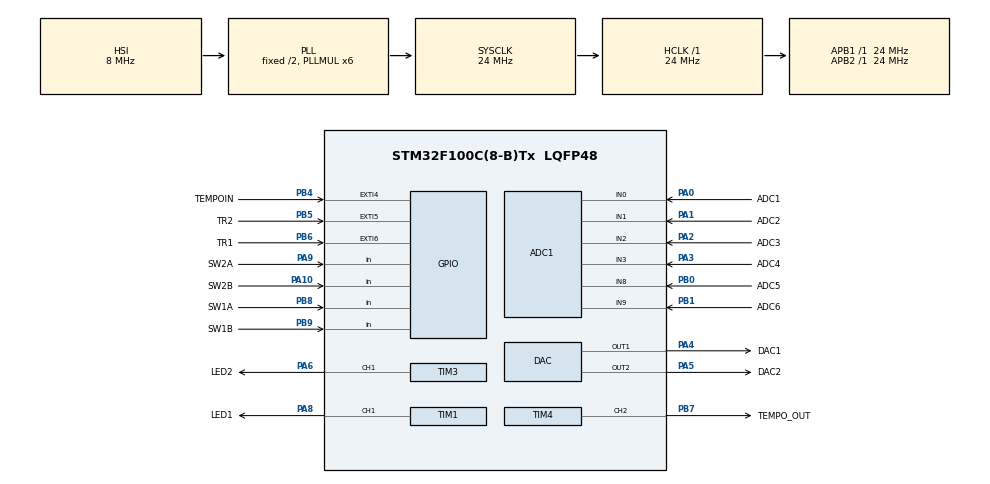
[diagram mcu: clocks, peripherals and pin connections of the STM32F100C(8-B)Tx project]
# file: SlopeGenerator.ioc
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ADC1.Channel-0\#ChannelRegularConversion=ADC_CHANNEL_0
ADC1.Channel-1\#ChannelRegularConversion=ADC_CHANNEL_1
ADC1.Channel-2\#ChannelRegularConversion=ADC_CHANNEL_2
ADC1.Channel-3\#ChannelRegularConversion=ADC_CHANNEL_3
ADC1.Channel-4\#ChannelRegularConversion=ADC_CHANNEL_8
ADC1.Channel-5\#ChannelRegularConversion=ADC_CHANNEL_9
ADC1.ContinuousConvMode=ENABLE
ADC1.DataAlign=ADC_DATAALIGN_RIGHT
ADC1.DiscontinuousConvMode=DISABLE
ADC1.EnableAnalogWatchDog=false
ADC1.EnableRegularConversion=ENABLE
ADC1.ExternalTrigConv=ADC_SOFTWARE_START
ADC1.InjNumberOfConversion=0
ADC1.NbrOfConversion=6
ADC1.NbrOfConversionFlag=1
ADC1.Rank-0\#ChannelRegularConversion=1
ADC1.Rank-1\#ChannelRegularConversion=2
ADC1.Rank-2\#ChannelRegularConversion=3
ADC1.Rank-3\#ChannelRegularConversion=4
ADC1.Rank-4\#ChannelRegularConversion=5
ADC1.Rank-5\#ChannelRegularConversion=6
ADC1.SamplingTime-0\#ChannelRegularConversion=ADC_SAMPLETIME_71CYCLES_5
ADC1.SamplingTime-1\#ChannelRegularConversion=ADC_SAMPLETIME_71CYCLES_5
ADC1.SamplingTime-2\#ChannelRegularConversion=ADC_SAMPLETIME_71CYCLES_5
ADC1.SamplingTime-3\#ChannelRegularConversion=ADC_SAMPLETIME_71CYCLES_5
ADC1.SamplingTime-4\#ChannelRegularConversion=ADC_SAMPLETIME_71CYCLES_5
ADC1.SamplingTime-5\#ChannelRegularConversion=ADC_SAMPLETIME_71CYCLES_5
ADC1.ScanConvMode=ADC_SCAN_ENABLE
ADC1.master=1
DAC.DAC_OutputBuffer=DAC_OUTPUTBUFFER_DISABLE
DAC.DAC_OutputBuffer2=DAC_OUTPUTBUFFER_DISABLE
DAC.DAC_Trigger=DAC_TRIGGER_T6_TRGO
DAC.DAC_Trigger2=DAC_TRIGGER_T6_TRGO
Dma.ADC1.2.Direction=DMA_PERIPH_TO_MEMORY
Dma.ADC1.2.Instance=DMA1_Channel1
Dma.ADC1.2.MemDataAlignment=DMA_MDATAALIGN_HALFWORD
Dma.ADC1.2.MemInc=DMA_MINC_ENABLE
Dma.ADC1.2.Mode=DMA_CIRCULAR
Dma.ADC1.2.PeriphDataAlignment=DMA_PDATAALIGN_HALFWORD
Dma.ADC1.2.PeriphInc=DMA_PINC_DISABLE
Dma.ADC1.2.Priority=DMA_PRIORITY_LOW
Dma.DAC_CH1.0.Direction=DMA_MEMORY_TO_PERIPH
Dma.DAC_CH1.0.Instance=DMA1_Channel3
Dma.DAC_CH1.0.MemDataAlignment=DMA_MDATAALIGN_HALFWORD
Dma.DAC_CH1.0.MemInc=DMA_MINC_ENABLE
Dma.DAC_CH1.0.Mode=DMA_CIRCULAR
Dma.DAC_CH1.0.PeriphDataAlignment=DMA_PDATAALIGN_HALFWORD
Dma.DAC_CH1.0.PeriphInc=DMA_PINC_DISABLE
Dma.DAC_CH1.0.Priority=DMA_PRIORITY_LOW
Dma.DAC_CH2.1.Direction=DMA_MEMORY_TO_PERIPH
Dma.DAC_CH2.1.Instance=DMA1_Channel4
Dma.DAC_CH2.1.MemDataAlignment=DMA_MDATAALIGN_HALFWORD
Dma.DAC_CH2.1.MemInc=DMA_MINC_ENABLE
Dma.DAC_CH2.1.Mode=DMA_CIRCULAR
Dma.DAC_CH2.1.PeriphDataAlignment=DMA_PDATAALIGN_HALFWORD
Dma.DAC_CH2.1.PeriphInc=DMA_PINC_DISABLE
Dma.DAC_CH2.1.Priority=DMA_PRIORITY_LOW
Dma.Request0=DAC_CH1
Dma.Request1=DAC_CH2
Dma.Request2=ADC1
Mcu.Family=STM32F1
Mcu.Name=STM32F100C(8-B)Tx
Mcu.Package=LQFP48
NVIC.DMA1_Channel1_IRQn=true\:2\:0\:true\:false\:true
NVIC.DMA1_Channel3_IRQn=true\:2\:0\:true\:false\:true
NVIC.DMA1_Channel4_IRQn=true\:2\:0\:true\:false\:true
NVIC.EXTI4_IRQn=true\:15\:0\:true\:false\:true
NVIC.EXTI9_5_IRQn=true\:15\:0\:true\:false\:true
NVIC.PriorityGroup=NVIC_PRIORITYGROUP_4
NVIC.TIM2_IRQn=true\:5\:0\:true\:false\:true
PA0-WKUP.GPIO_Label=ADC1
PA0-WKUP.Signal=ADCx_IN0
PA1.GPIO_Label=ADC2
PA1.Signal=ADCx_IN1
PA10.GPIO_Label=SW2B
PA10.GPIO_PuPd=GPIO_PULLUP
PA10.Signal=GPIO_Input
PA13.Mode=Serial_Wire
PA13.Signal=SYS_JTMS-SWDIO
PA14.Mode=Serial_Wire
PA14.Signal=SYS_JTCK-SWCLK
PA2.GPIO_Label=ADC3
PA2.Signal=ADCx_IN2
PA3.GPIO_Label=ADC4
PA3.Signal=ADCx_IN3
PA4.GPIO_Label=DAC1
PA4.Signal=COMP_DAC1_group
PA5.GPIO_Label=DAC2
PA5.Signal=COMP_DAC2_group
PA6.GPIO_Label=LED2
PA6.Signal=S_TIM3_CH1
PA8.GPIO_Label=LED1
PA8.Signal=S_TIM1_CH1
PA9.GPIO_Label=SW2A
PA9.GPIO_PuPd=GPIO_PULLUP
PA9.Signal=GPIO_Input
PB0.GPIO_Label=ADC5
PB0.Signal=ADCx_IN8
PB1.GPIO_Label=ADC6
PB1.Signal=ADCx_IN9
PB4.GPIO_Label=TEMPOIN
PB4.GPIO_ModeDefaultEXTI=GPIO_MODE_IT_FALLING
PB4.GPIO_PuPd=GPIO_PULLUP
PB4.Signal=GPXTI4
PB5.GPIO_Label=TR2
PB5.GPIO_ModeDefaultEXTI=GPIO_MODE_IT_FALLING
PB5.GPIO_PuPd=GPIO_PULLUP
PB5.Signal=GPXTI5
PB6.GPIO_Label=TR1
PB6.GPIO_ModeDefaultEXTI=GPIO_MODE_IT_FALLING
PB6.GPIO_PuPd=GPIO_PULLUP
PB6.Signal=GPXTI6
PB7.GPIO_Label=TEMPO_OUT
PB7.Signal=S_TIM4_CH2
PB8.GPIO_Label=SW1A
PB8.GPIO_PuPd=GPIO_PULLUP
PB8.Signal=GPIO_Input
PB9.GPIO_Label=SW1B
PB9.GPIO_PuPd=GPIO_PULLUP
PB9.Signal=GPIO_Input
PD0-OSC_IN.Mode=HSE-External-Oscillator
PD0-OSC_IN.Signal=RCC_OSC_IN
PD1-OSC_OUT.Mode=HSE-External-Oscillator
PD1-OSC_OUT.Signal=RCC_OSC_OUT
ProjectManager.HeapSize=0x200
ProjectManager.StackSize=0x400
ProjectManager.TargetToolchain=TrueSTUDIO
RCC.ADCPresc=RCC_ADCPCLK2_DIV8
RCC.AHBFreq_Value=24000000
RCC.APB1Freq_Value=24000000
RCC.APB1TimFreq_Value=24000000
RCC.APB2Freq_Value=24000000
RCC.APB2TimFreq_Value=24000000
RCC.HCLKFreq_Value=24000000
RCC.PLLMUL=RCC_PLL_MUL6
RCC.SYSCLKFreq_VALUE=24000000
RCC.SYSCLKSource=RCC_SYSCLKSOURCE_PLLCLK
SH.ADCx_IN0.0=ADC1_IN0,IN0
SH.ADCx_IN1.0=ADC1_IN1,IN1
SH.ADCx_IN2.0=ADC1_IN2,IN2
SH.ADCx_IN3.0=ADC1_IN3,IN3
SH.ADCx_IN8.0=ADC1_IN8,IN8
SH.ADCx_IN9.0=ADC1_IN9,IN9
SH.COMP_DAC1_group.0=DAC_OUT1,DAC_OUT1
SH.COMP_DAC2_group.0=DAC_OUT2,DAC_OUT2
SH.S_TIM1_CH1.0=TIM1_CH1,PWM Generation1 CH1
SH.S_TIM3_CH1.0=TIM3_CH1,PWM Generation1 CH1
SH.S_TIM4_CH2.0=TIM4_CH2,PWM Generation2 CH2
TIM1.Period=1000
TIM1.Prescaler=24
TIM1.TIM_MasterOutputTrigger=TIM_TRGO_RESET
TIM2.Period=2000
TIM2.TIM_MasterOutputTrigger=TIM_TRGO_UPDATE
TIM3.Period=1000
TIM3.Prescaler=24
TIM3.TIM_MasterOutputTrigger=TIM_TRGO_RESET
TIM4.Channel-PWM\ Generation2\ CH2=TIM_CHANNEL_2
TIM4.Period=7500
TIM4.Prescaler=2400
TIM4.Pulse-PWM\ Generation2\ CH2=1023
TIM6.Period=12000
TIM6.TIM_MasterOutputTrigger=TIM_TRGO_UPDATE
VP_TIM2_VS_no_output1.Mode=Output Compare1 No Output
VP_TIM6_VS_ClockSourceINT.Mode=Enable_Timer
board=SlopeGenerator

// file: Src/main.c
/**
  ******************************************************************************
  * File Name          : main.c
  * Description        : Main program body
  ******************************************************************************
  *
  * COPYRIGHT(c) 2017 STMicroelectronics
  *
  * Redistribution and use in source and binary forms, with or without modification,
  * are permitted provided that the following conditions are met:
  *   1. Redistributions of source code must retain the above copyright notice,
  *      this list of conditions and the following disclaimer.
  *   2. Redistributions in binary form must reproduce the above copyright notice,
  *      this list of conditions and the following disclaimer in the documentation
  *      and/or other materials provided with the distribution.
  *   3. Neither the name of STMicroelectronics nor the names of its contributors
  *      may be used to endorse or promote products derived from this software
  *      without specific prior written permission.
  *
  * THIS SOFTWARE IS PROVIDED BY THE COPYRIGHT HOLDERS AND CONTRIBUTORS "AS IS"
  * AND ANY EXPRESS OR IMPLIED WARRANTIES, INCLUDING, BUT NOT LIMITED TO, THE
  * IMPLIED WARRANTIES OF MERCHANTABILITY AND FITNESS FOR A PARTICULAR PURPOSE ARE
  * DISCLAIMED. IN NO EVENT SHALL THE COPYRIGHT HOLDER OR CONTRIBUTORS BE LIABLE
  * FOR ANY DIRECT, INDIRECT, INCIDENTAL, SPECIAL, EXEMPLARY, OR CONSEQUENTIAL
  * DAMAGES (INCLUDING, BUT NOT LIMITED TO, PROCUREMENT OF SUBSTITUTE GOODS OR
  * SERVICES; LOSS OF USE, DATA, OR PROFITS; OR BUSINESS INTERRUPTION) HOWEVER
  * CAUSED AND ON ANY THEORY OF LIABILITY, WHETHER IN CONTRACT, STRICT LIABILITY,
  * OR TORT (INCLUDING NEGLIGENCE OR OTHERWISE) ARISING IN ANY WAY OUT OF THE USE
  * OF THIS SOFTWARE, EVEN IF ADVISED OF THE POSSIBILITY OF SUCH DAMAGE.
  *
  ******************************************************************************
  */
#include "main.h"
#include "stm32f1xx_hal.h"

ADC_HandleTypeDef hadc1;
DMA_HandleTypeDef hdma_adc1;

DAC_HandleTypeDef hdac;
DMA_HandleTypeDef hdma_dac_ch1;
DMA_HandleTypeDef hdma_dac_ch2;

TIM_HandleTypeDef htim1;
TIM_HandleTypeDef htim2;
TIM_HandleTypeDef htim3;
TIM_HandleTypeDef htim4;
TIM_HandleTypeDef htim6;

/* USER CODE BEGIN PV */
/* Private variables ---------------------------------------------------------*/

/* USER CODE END PV */

void SystemClock_Config(void);
void Error_Handler(void);
static void MX_GPIO_Init(void);
static void MX_DMA_Init(void);
static void MX_ADC1_Init(void);
static void MX_DAC_Init(void);
static void MX_TIM1_Init(void);
static void MX_TIM2_Init(void);
static void MX_TIM3_Init(void);
static void MX_TIM6_Init(void);
static void MX_TIM4_Init(void);

void HAL_TIM_MspPostInit(TIM_HandleTypeDef *htim);

/* USER CODE BEGIN PFP */
/* Private function prototypes -----------------------------------------------*/
extern void setup();
extern void loop();

/* USER CODE END PFP */

int main(void)
{

  /* MCU Configuration----------------------------------------------------------*/

  /* Reset of all peripherals, Initializes the Flash interface and the Systick. */
  HAL_Init();

  /* Configure the system clock */
  SystemClock_Config();

  /* Initialize all configured peripherals */
  MX_GPIO_Init();
  MX_DMA_Init();
  MX_ADC1_Init();
  MX_DAC_Init();
  MX_TIM1_Init();
  MX_TIM2_Init();
  MX_TIM3_Init();
  MX_TIM6_Init();
  MX_TIM4_Init();

  /* USER CODE BEGIN 2 */
  setup();
  /* USER CODE END 2 */

  /* Infinite loop */
  /* USER CODE BEGIN WHILE */
  while (1)
  {
    loop();
  /* USER CODE END WHILE */

  }

}

/** System Clock Configuration
*/
void SystemClock_Config(void)
{

  RCC_OscInitTypeDef RCC_OscInitStruct;
  RCC_ClkInitTypeDef RCC_ClkInitStruct;
  RCC_PeriphCLKInitTypeDef PeriphClkInit;

    /**Initializes the CPU, AHB and APB busses clocks
    */
  RCC_OscInitStruct.OscillatorType = RCC_OSCILLATORTYPE_HSI;
  RCC_OscInitStruct.HSIState = RCC_HSI_ON;
  RCC_OscInitStruct.HSICalibrationValue = 16;
  RCC_OscInitStruct.PLL.PLLState = RCC_PLL_ON;
  RCC_OscInitStruct.PLL.PLLSource = RCC_PLLSOURCE_HSI_DIV2;
  RCC_OscInitStruct.PLL.PLLMUL = RCC_PLL_MUL6;
  if (HAL_RCC_OscConfig(&RCC_OscInitStruct) != HAL_OK)
  {
    Error_Handler();
  }

    /**Initializes the CPU, AHB and APB busses clocks
    */
  RCC_ClkInitStruct.ClockType = RCC_CLOCKTYPE_HCLK|RCC_CLOCKTYPE_SYSCLK
                              |RCC_CLOCKTYPE_PCLK1|RCC_CLOCKTYPE_PCLK2;
  RCC_ClkInitStruct.SYSCLKSource = RCC_SYSCLKSOURCE_PLLCLK;
  RCC_ClkInitStruct.AHBCLKDivider = RCC_SYSCLK_DIV1;
  RCC_ClkInitStruct.APB1CLKDivider = RCC_HCLK_DIV1;
  RCC_ClkInitStruct.APB2CLKDivider = RCC_HCLK_DIV1;

  if (HAL_RCC_ClockConfig(&RCC_ClkInitStruct, FLASH_LATENCY_0) != HAL_OK)
  {
    Error_Handler();
  }

  PeriphClkInit.PeriphClockSelection = RCC_PERIPHCLK_ADC;
  PeriphClkInit.AdcClockSelection = RCC_ADCPCLK2_DIV8;
  if (HAL_RCCEx_PeriphCLKConfig(&PeriphClkInit) != HAL_OK)
  {
    Error_Handler();
  }

    /**Configure the Systick interrupt time
    */
  HAL_SYSTICK_Config(HAL_RCC_GetHCLKFreq()/1000);

    /**Configure the Systick
    */
  HAL_SYSTICK_CLKSourceConfig(SYSTICK_CLKSOURCE_HCLK);

  /* SysTick_IRQn interrupt configuration */
  HAL_NVIC_SetPriority(SysTick_IRQn, 0, 0);
}

/* ADC1 init function */
static void MX_ADC1_Init(void)
{

  ADC_ChannelConfTypeDef sConfig;

    /**Common config
    */
  hadc1.Instance = ADC1;
  hadc1.Init.ScanConvMode = ADC_SCAN_ENABLE;
  hadc1.Init.ContinuousConvMode = ENABLE;
  hadc1.Init.DiscontinuousConvMode = DISABLE;
  hadc1.Init.ExternalTrigConv = ADC_SOFTWARE_START;
  hadc1.Init.DataAlign = ADC_DATAALIGN_RIGHT;
  hadc1.Init.NbrOfConversion = 6;
  if (HAL_ADC_Init(&hadc1) != HAL_OK)
  {
    Error_Handler();
  }

    /**Configure Regular Channel
    */
  sConfig.Channel = ADC_CHANNEL_0;
  sConfig.Rank = 1;
  sConfig.SamplingTime = ADC_SAMPLETIME_71CYCLES_5;
  if (HAL_ADC_ConfigChannel(&hadc1, &sConfig) != HAL_OK)
  {
    Error_Handler();
  }

    /**Configure Regular Channel
    */
  sConfig.Channel = ADC_CHANNEL_1;
  sConfig.Rank = 2;
  if (HAL_ADC_ConfigChannel(&hadc1, &sConfig) != HAL_OK)
  {
    Error_Handler();
  }

    /**Configure Regular Channel
    */
  sConfig.Channel = ADC_CHANNEL_2;
  sConfig.Rank = 3;
  if (HAL_ADC_ConfigChannel(&hadc1, &sConfig) != HAL_OK)
  {
    Error_Handler();
  }

    /**Configure Regular Channel
    */
  sConfig.Channel = ADC_CHANNEL_3;
  sConfig.Rank = 4;
  if (HAL_ADC_ConfigChannel(&hadc1, &sConfig) != HAL_OK)
  {
    Error_Handler();
  }

    /**Configure Regular Channel
    */
  sConfig.Channel = ADC_CHANNEL_8;
  sConfig.Rank = 5;
  if (HAL_ADC_ConfigChannel(&hadc1, &sConfig) != HAL_OK)
  {
    Error_Handler();
  }

    /**Configure Regular Channel
    */
  sConfig.Channel = ADC_CHANNEL_9;
  sConfig.Rank = 6;
  if (HAL_ADC_ConfigChannel(&hadc1, &sConfig) != HAL_OK)
  {
    Error_Handler();
  }

}

/* DAC init function */
static void MX_DAC_Init(void)
{

  DAC_ChannelConfTypeDef sConfig;

    /**DAC Initialization
    */
  hdac.Instance = DAC;
  if (HAL_DAC_Init(&hdac) != HAL_OK)
  {
    Error_Handler();
  }

    /**DAC channel OUT1 config
    */
  sConfig.DAC_Trigger = DAC_TRIGGER_T6_TRGO;
  sConfig.DAC_OutputBuffer = DAC_OUTPUTBUFFER_DISABLE;
  if (HAL_DAC_ConfigChannel(&hdac, &sConfig, DAC_CHANNEL_1) != HAL_OK)
  {
    Error_Handler();
  }

    /**DAC channel OUT2 config
    */
  if (HAL_DAC_ConfigChannel(&hdac, &sConfig, DAC_CHANNEL_2) != HAL_OK)
  {
    Error_Handler();
  }

}

/* TIM1 init function */
static void MX_TIM1_Init(void)
{

  TIM_MasterConfigTypeDef sMasterConfig;
  TIM_OC_InitTypeDef sConfigOC;
  TIM_BreakDeadTimeConfigTypeDef sBreakDeadTimeConfig;

  htim1.Instance = TIM1;
  htim1.Init.Prescaler = 24;
  htim1.Init.CounterMode = TIM_COUNTERMODE_UP;
  htim1.Init.Period = 1000;
  htim1.Init.ClockDivision = TIM_CLOCKDIVISION_DIV1;
  htim1.Init.RepetitionCounter = 0;
  if (HAL_TIM_PWM_Init(&htim1) != HAL_OK)
  {
    Error_Handler();
  }

  sMasterConfig.MasterOutputTrigger = TIM_TRGO_RESET;
  sMasterConfig.MasterSlaveMode = TIM_MASTERSLAVEMODE_DISABLE;
  if (HAL_TIMEx_MasterConfigSynchronization(&htim1, &sMasterConfig) != HAL_OK)
  {
    Error_Handler();
  }

  sConfigOC.OCMode = TIM_OCMODE_PWM1;
  sConfigOC.Pulse = 0;
  sConfigOC.OCPolarity = TIM_OCPOLARITY_HIGH;
  sConfigOC.OCNPolarity = TIM_OCNPOLARITY_HIGH;
  sConfigOC.OCFastMode = TIM_OCFAST_DISABLE;
  sConfigOC.OCIdleState = TIM_OCIDLESTATE_RESET;
  sConfigOC.OCNIdleState = TIM_OCNIDLESTATE_RESET;
  if (HAL_TIM_PWM_ConfigChannel(&htim1, &sConfigOC, TIM_CHANNEL_1) != HAL_OK)
  {
    Error_Handler();
  }

  sBreakDeadTimeConfig.OffStateRunMode = TIM_OSSR_DISABLE;
  sBreakDeadTimeConfig.OffStateIDLEMode = TIM_OSSI_DISABLE;
  sBreakDeadTimeConfig.LockLevel = TIM_LOCKLEVEL_OFF;
  sBreakDeadTimeConfig.DeadTime = 0;
  sBreakDeadTimeConfig.BreakState = TIM_BREAK_DISABLE;
  sBreakDeadTimeConfig.BreakPolarity = TIM_BREAKPOLARITY_HIGH;
  sBreakDeadTimeConfig.AutomaticOutput = TIM_AUTOMATICOUTPUT_DISABLE;
  if (HAL_TIMEx_ConfigBreakDeadTime(&htim1, &sBreakDeadTimeConfig) != HAL_OK)
  {
    Error_Handler();
  }

  HAL_TIM_MspPostInit(&htim1);

}

/* TIM2 init function */
static void MX_TIM2_Init(void)
{

  TIM_MasterConfigTypeDef sMasterConfig;
  TIM_OC_InitTypeDef sConfigOC;

  htim2.Instance = TIM2;
  htim2.Init.Prescaler = 0;
  htim2.Init.CounterMode = TIM_COUNTERMODE_UP;
  htim2.Init.Period = 2000;
  htim2.Init.ClockDivision = TIM_CLOCKDIVISION_DIV1;
  if (HAL_TIM_OC_Init(&htim2) != HAL_OK)
  {
    Error_Handler();
  }

  sMasterConfig.MasterOutputTrigger = TIM_TRGO_UPDATE;
  sMasterConfig.MasterSlaveMode = TIM_MASTERSLAVEMODE_DISABLE;
  if (HAL_TIMEx_MasterConfigSynchronization(&htim2, &sMasterConfig) != HAL_OK)
  {
    Error_Handler();
  }

  sConfigOC.OCMode = TIM_OCMODE_TIMING;
  sConfigOC.Pulse = 0;
  sConfigOC.OCPolarity = TIM_OCPOLARITY_HIGH;
  sConfigOC.OCFastMode = TIM_OCFAST_DISABLE;
  if (HAL_TIM_OC_ConfigChannel(&htim2, &sConfigOC, TIM_CHANNEL_1) != HAL_OK)
  {
    Error_Handler();
  }

}

/* TIM3 init function */
static void MX_TIM3_Init(void)
{

  TIM_MasterConfigTypeDef sMasterConfig;
  TIM_OC_InitTypeDef sConfigOC;

  htim3.Instance = TIM3;
  htim3.Init.Prescaler = 24;
  htim3.Init.CounterMode = TIM_COUNTERMODE_UP;
  htim3.Init.Period = 1000;
  htim3.Init.ClockDivision = TIM_CLOCKDIVISION_DIV1;
  if (HAL_TIM_PWM_Init(&htim3) != HAL_OK)
  {
    Error_Handler();
  }

  sMasterConfig.MasterOutputTrigger = TIM_TRGO_RESET;
  sMasterConfig.MasterSlaveMode = TIM_MASTERSLAVEMODE_DISABLE;
  if (HAL_TIMEx_MasterConfigSynchronization(&htim3, &sMasterConfig) != HAL_OK)
  {
    Error_Handler();
  }

  sConfigOC.OCMode = TIM_OCMODE_PWM1;
  sConfigOC.Pulse = 0;
  sConfigOC.OCPolarity = TIM_OCPOLARITY_HIGH;
  sConfigOC.OCFastMode = TIM_OCFAST_DISABLE;
  if (HAL_TIM_PWM_ConfigChannel(&htim3, &sConfigOC, TIM_CHANNEL_1) != HAL_OK)
  {
    Error_Handler();
  }

  HAL_TIM_MspPostInit(&htim3);

}

/* TIM4 init function */
static void MX_TIM4_Init(void)
{

  TIM_MasterConfigTypeDef sMasterConfig;
  TIM_OC_InitTypeDef sConfigOC;

  htim4.Instance = TIM4;
  htim4.Init.Prescaler = 2400;
  htim4.Init.CounterMode = TIM_COUNTERMODE_UP;
  htim4.Init.Period = 7500;
  htim4.Init.ClockDivision = TIM_CLOCKDIVISION_DIV1;
  if (HAL_TIM_PWM_Init(&htim4) != HAL_OK)
  {
    Error_Handler();
  }

  sMasterConfig.MasterOutputTrigger = TIM_TRGO_RESET;
  sMasterConfig.MasterSlaveMode = TIM_MASTERSLAVEMODE_DISABLE;
  if (HAL_TIMEx_MasterConfigSynchronization(&htim4, &sMasterConfig) != HAL_OK)
  {
    Error_Handler();
  }

  sConfigOC.OCMode = TIM_OCMODE_PWM1;
  sConfigOC.Pulse = 1023;
  sConfigOC.OCPolarity = TIM_OCPOLARITY_HIGH;
  sConfigOC.OCFastMode = TIM_OCFAST_DISABLE;
  if (HAL_TIM_PWM_ConfigChannel(&htim4, &sConfigOC, TIM_CHANNEL_2) != HAL_OK)
  {
    Error_Handler();
  }

  HAL_TIM_MspPostInit(&htim4);

}

/* TIM6 init function */
static void MX_TIM6_Init(void)
{

  TIM_MasterConfigTypeDef sMasterConfig;

  htim6.Instance = TIM6;
  htim6.Init.Prescaler = 0;
  htim6.Init.CounterMode = TIM_COUNTERMODE_UP;
  htim6.Init.Period = 12000;
  if (HAL_TIM_Base_Init(&htim6) != HAL_OK)
  {
    Error_Handler();
  }

  sMasterConfig.MasterOutputTrigger = TIM_TRGO_UPDATE;
  sMasterConfig.MasterSlaveMode = TIM_MASTERSLAVEMODE_DISABLE;
  if (HAL_TIMEx_MasterConfigSynchronization(&htim6, &sMasterConfig) != HAL_OK)
  {
    Error_Handler();
  }

}

static void MX_DMA_Init(void)
{
  /* DMA controller clock enable */
  __HAL_RCC_DMA1_CLK_ENABLE();

  /* DMA interrupt init */
  /* DMA1_Channel1_IRQn interrupt configuration */
  HAL_NVIC_SetPriority(DMA1_Channel1_IRQn, 2, 0);
  HAL_NVIC_EnableIRQ(DMA1_Channel1_IRQn);
  /* DMA1_Channel3_IRQn interrupt configuration */
  HAL_NVIC_SetPriority(DMA1_Channel3_IRQn, 2, 0);
  HAL_NVIC_EnableIRQ(DMA1_Channel3_IRQn);
  /* DMA1_Channel4_IRQn interrupt configuration */
  HAL_NVIC_SetPriority(DMA1_Channel4_IRQn, 2, 0);
  HAL_NVIC_EnableIRQ(DMA1_Channel4_IRQn);

}

/** Configure pins as
        * Analog
        * Input
        * Output
        * EVENT_OUT
        * EXTI
*/
static void MX_GPIO_Init(void)
{

  GPIO_InitTypeDef GPIO_InitStruct;

  /* GPIO Ports Clock Enable */
  __HAL_RCC_GPIOD_CLK_ENABLE();
  __HAL_RCC_GPIOA_CLK_ENABLE();
  __HAL_RCC_GPIOB_CLK_ENABLE();

  /*Configure GPIO pins : SW2A_Pin SW2B_Pin */
  GPIO_InitStruct.Pin = SW2A_Pin|SW2B_Pin;
  GPIO_InitStruct.Mode = GPIO_MODE_INPUT;
  GPIO_InitStruct.Pull = GPIO_PULLUP;
  HAL_GPIO_Init(GPIOA, &GPIO_InitStruct);

  /*Configure GPIO pins : TEMPOIN_Pin TR2_Pin TR1_Pin */
  GPIO_InitStruct.Pin = TEMPOIN_Pin|TR2_Pin|TR1_Pin;
  GPIO_InitStruct.Mode = GPIO_MODE_IT_FALLING;
  GPIO_InitStruct.Pull = GPIO_PULLUP;
  HAL_GPIO_Init(GPIOB, &GPIO_InitStruct);

  /*Configure GPIO pins : SW1A_Pin SW1B_Pin */
  GPIO_InitStruct.Pin = SW1A_Pin|SW1B_Pin;
  GPIO_InitStruct.Mode = GPIO_MODE_INPUT;
  GPIO_InitStruct.Pull = GPIO_PULLUP;
  HAL_GPIO_Init(GPIOB, &GPIO_InitStruct);

  /* EXTI interrupt init*/
  HAL_NVIC_SetPriority(EXTI4_IRQn, 15, 0);
  HAL_NVIC_EnableIRQ(EXTI4_IRQn);

  HAL_NVIC_SetPriority(EXTI9_5_IRQn, 15, 0);
  HAL_NVIC_EnableIRQ(EXTI9_5_IRQn);

}

void Error_Handler(void)
{
  while(1)
  {
  }
}

/************************ (C) COPYRIGHT STMicroelectronics *****END OF FILE****/
